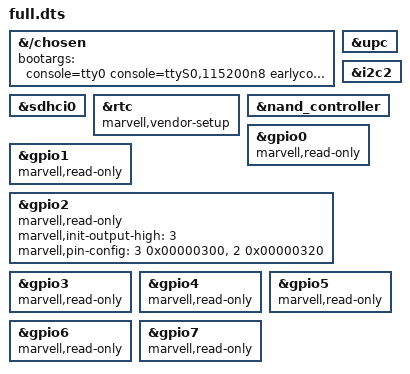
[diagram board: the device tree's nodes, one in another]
// SPDX-License-Identifier: GPL-2.0
/*
 * full variant: SD, UPC, GPIO (read-only), I2C bus 2, the RTC (read-only)
 * and the NAND (read-only) enabled; consoleblank=0 for the panel console.
 */
#include "88pa6170-dp200.dts"

&{/chosen} {
	bootargs = "console=tty0 console=ttyS0,115200n8 earlycon=uart8250,mmio32,0xf8060000 rdinit=/init panic=10 consoleblank=0";
};

&sdhci0 { status = "okay"; };
&upc { status = "okay"; };
&i2c2 { status = "okay"; };
/*
 * RTC: the vendor setup (user-approved 2026-10-30, corrected +0x20 values).
 * set_time (marvell,set-time) stays off until the user OKs it.
 */
&rtc {
	status = "okay";
	marvell,vendor-setup;
};
&nand_controller { status = "okay"; };
&gpio0 { status = "okay"; marvell,read-only; };
&gpio1 { status = "okay"; marvell,read-only; };
/*
 * Touch controller (BU21029, I2C bus 2 at 0x40): GPIO 67 (bank 2 line 3) is
 * its reset/enable, driven high as stock (gr_def_mpp_list); GPIO 66 (line 2)
 * is its interrupt input. Pin selects as stock (0x300, 0x320). User-approved
 * (touch-pins test). The bank stays read-only at runtime.
 */
&gpio2 {
	status = "okay";
	marvell,read-only;
	marvell,init-output-high = <3>;
	marvell,pin-config = <3 0x00000300>, <2 0x00000320>;
};
&gpio3 { status = "okay"; marvell,read-only; };
&gpio4 { status = "okay"; marvell,read-only; };
&gpio5 { status = "okay"; marvell,read-only; };
&gpio6 { status = "okay"; marvell,read-only; };
&gpio7 { status = "okay"; marvell,read-only; };
